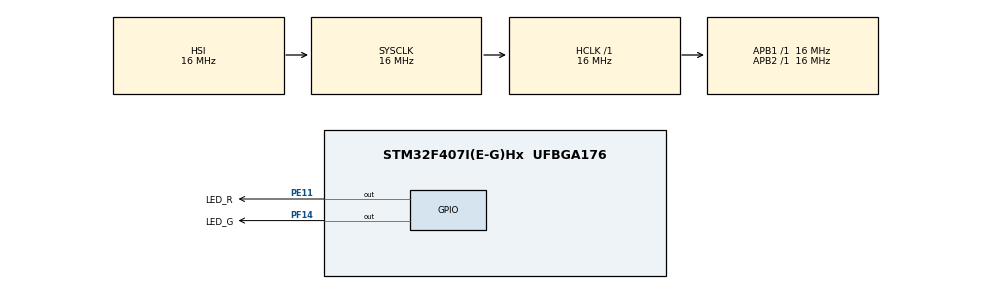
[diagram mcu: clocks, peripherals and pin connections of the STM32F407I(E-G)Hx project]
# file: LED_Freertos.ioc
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FREERTOS.Tasks01=LED_R,-1,128,StartDefaultTask,Default,NULL,Dynamic,NULL,NULL;LED_G,0,128,StartTask02,Default,NULL,Dynamic,NULL,NULL
Mcu.Family=STM32F4
Mcu.Name=STM32F407I(E-G)Hx
Mcu.Package=UFBGA176
NVIC.PriorityGroup=NVIC_PRIORITYGROUP_4
NVIC.TIM1_UP_TIM10_IRQn=true\:15\:0\:false\:false\:true\:false\:false\:true\:true
NVIC.TimeBase=TIM1_UP_TIM10_IRQn
NVIC.TimeBaseIP=TIM1
PA13.Mode=Serial_Wire
PA13.Signal=SYS_JTMS-SWDIO
PA14.Mode=Serial_Wire
PA14.Signal=SYS_JTCK-SWCLK
PC14-OSC32_IN.Mode=LSE-External-Oscillator
PC14-OSC32_IN.Signal=RCC_OSC32_IN
PC15-OSC32_OUT.Mode=LSE-External-Oscillator
PC15-OSC32_OUT.Signal=RCC_OSC32_OUT
PE11.GPIO_Label=LED_R
PE11.Signal=GPIO_Output
PF14.GPIO_Label=LED_G
PF14.Signal=GPIO_Output
PH0-OSC_IN.Mode=HSE-External-Oscillator
PH0-OSC_IN.Signal=RCC_OSC_IN
PH1-OSC_OUT.Mode=HSE-External-Oscillator
PH1-OSC_OUT.Signal=RCC_OSC_OUT
ProjectManager.HeapSize=0x200
ProjectManager.StackSize=0x400
ProjectManager.TargetToolchain=MDK-ARM V5.32
RCC.AHBFreq_Value=16000000
RCC.APB1Freq_Value=16000000
RCC.APB2Freq_Value=16000000
RCC.CortexFreq_Value=16000000
RCC.HSE_VALUE=25000000
RCC.HSI_VALUE=16000000
RCC.SYSCLKFreq_VALUE=16000000
RCC.VCOOutputFreq_Value=192000000
VP_FREERTOS_VS_CMSIS_V1.Mode=CMSIS_V1
VP_SYS_VS_tim1.Mode=TIM1
board=custom

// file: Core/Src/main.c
/* USER CODE BEGIN Header */
/**
  ******************************************************************************
  * @file           : main.c
  * @brief          : Main program body
  ******************************************************************************
  * @attention
  *
  * Copyright (c) 2023 STMicroelectronics.
  * All rights reserved.
  *
  * This software is licensed under terms that can be found in the LICENSE file
  * in the root directory of this software component.
  * If no LICENSE file comes with this software, it is provided AS-IS.
  *
  ******************************************************************************
  */
/* USER CODE END Header */
#include "main.h"
#include "cmsis_os.h"
#include "gpio.h"

void SystemClock_Config(void);
void MX_FREERTOS_Init(void);

int main(void)
{

  /* MCU Configuration--------------------------------------------------------*/

  /* Reset of all peripherals, Initializes the Flash interface and the Systick. */
  HAL_Init();

  /* Configure the system clock */
  SystemClock_Config();

  /* Initialize all configured peripherals */
  MX_GPIO_Init();

  /* Call init function for freertos objects (in freertos.c) */
  MX_FREERTOS_Init();

  /* Start scheduler */
  osKernelStart();
  /* We should never get here as control is now taken by the scheduler */
  /* Infinite loop */
  while (1)
  {

  }
}

void SystemClock_Config(void)
{
  RCC_OscInitTypeDef RCC_OscInitStruct = {0};
  RCC_ClkInitTypeDef RCC_ClkInitStruct = {0};

  /** Configure the main internal regulator output voltage
  */
  __HAL_RCC_PWR_CLK_ENABLE();
  __HAL_PWR_VOLTAGESCALING_CONFIG(PWR_REGULATOR_VOLTAGE_SCALE1);

  /** Initializes the RCC Oscillators according to the specified parameters
  * in the RCC_OscInitTypeDef structure.
  */
  RCC_OscInitStruct.OscillatorType = RCC_OSCILLATORTYPE_HSI;
  RCC_OscInitStruct.HSIState = RCC_HSI_ON;
  RCC_OscInitStruct.HSICalibrationValue = RCC_HSICALIBRATION_DEFAULT;
  RCC_OscInitStruct.PLL.PLLState = RCC_PLL_NONE;
  if (HAL_RCC_OscConfig(&RCC_OscInitStruct) != HAL_OK)
  {
    Error_Handler();
  }

  /** Initializes the CPU, AHB and APB buses clocks
  */
  RCC_ClkInitStruct.ClockType = RCC_CLOCKTYPE_HCLK|RCC_CLOCKTYPE_SYSCLK
                              |RCC_CLOCKTYPE_PCLK1|RCC_CLOCKTYPE_PCLK2;
  RCC_ClkInitStruct.SYSCLKSource = RCC_SYSCLKSOURCE_HSI;
  RCC_ClkInitStruct.AHBCLKDivider = RCC_SYSCLK_DIV1;
  RCC_ClkInitStruct.APB1CLKDivider = RCC_HCLK_DIV1;
  RCC_ClkInitStruct.APB2CLKDivider = RCC_HCLK_DIV1;

  if (HAL_RCC_ClockConfig(&RCC_ClkInitStruct, FLASH_LATENCY_0) != HAL_OK)
  {
    Error_Handler();
  }
}

void HAL_TIM_PeriodElapsedCallback(TIM_HandleTypeDef *htim)
{
  if (htim->Instance == TIM1) {
    HAL_IncTick();
  }
}

void Error_Handler(void)
{
  __disable_irq();
  while (1)
  {
  }
}

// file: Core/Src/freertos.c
/* USER CODE BEGIN Header */
/**
  ******************************************************************************
  * File Name          : freertos.c
  * Description        : Code for freertos applications
  ******************************************************************************
  * @attention
  *
  * Copyright (c) 2023 STMicroelectronics.
  * All rights reserved.
  *
  * This software is licensed under terms that can be found in the LICENSE file
  * in the root directory of this software component.
  * If no LICENSE file comes with this software, it is provided AS-IS.
  *
  ******************************************************************************
  */
/* USER CODE END Header */

#include "FreeRTOS.h"
#include "task.h"
#include "main.h"
#include "cmsis_os.h"

osThreadId LED_RHandle;
osThreadId LED_GHandle;

void StartDefaultTask(void const * argument);
void StartTask02(void const * argument);

void MX_FREERTOS_Init(void); /* (MISRA C 2004 rule 8.1) */

/* GetIdleTaskMemory prototype (linked to static allocation support) */
void vApplicationGetIdleTaskMemory( StaticTask_t **ppxIdleTaskTCBBuffer, StackType_t **ppxIdleTaskStackBuffer, uint32_t *pulIdleTaskStackSize );

/* USER CODE BEGIN GET_IDLE_TASK_MEMORY */
static StaticTask_t xIdleTaskTCBBuffer;
static StackType_t xIdleStack[configMINIMAL_STACK_SIZE];

void vApplicationGetIdleTaskMemory( StaticTask_t **ppxIdleTaskTCBBuffer, StackType_t **ppxIdleTaskStackBuffer, uint32_t *pulIdleTaskStackSize )
{
  *ppxIdleTaskTCBBuffer = &xIdleTaskTCBBuffer;
  *ppxIdleTaskStackBuffer = &xIdleStack[0];
  *pulIdleTaskStackSize = configMINIMAL_STACK_SIZE;
  /* place for user code */
}
/* USER CODE END GET_IDLE_TASK_MEMORY */

void MX_FREERTOS_Init(void) {

  /* Create the thread(s) */
  /* definition and creation of LED_R */
  osThreadDef(LED_R, StartDefaultTask, osPriorityBelowNormal, 0, 128);
  LED_RHandle = osThreadCreate(osThread(LED_R), NULL);

  /* definition and creation of LED_G */
  osThreadDef(LED_G, StartTask02, osPriorityNormal, 0, 128);
  LED_GHandle = osThreadCreate(osThread(LED_G), NULL);

}

void StartDefaultTask(void const * argument)
{
  /* USER CODE BEGIN StartDefaultTask */
  /* Infinite loop */
  for(;;)
  {
    HAL_GPIO_WritePin(LED_R_GPIO_Port,LED_R_Pin,GPIO_PIN_RESET);
    osDelay(1);
	HAL_GPIO_WritePin(LED_R_GPIO_Port,LED_R_Pin,GPIO_PIN_RESET);
    osDelay(1);
	HAL_GPIO_WritePin(LED_R_GPIO_Port,LED_R_Pin,GPIO_PIN_SET);
    osDelay(1);
  }
  /* USER CODE END StartDefaultTask */
}

void StartTask02(void const * argument)
{
  /* USER CODE BEGIN StartTask02 */
  /* Infinite loop */
  for(;;)
  {
	HAL_GPIO_WritePin(LED_G_GPIO_Port,LED_G_Pin,GPIO_PIN_RESET);
    osDelay(1);
	HAL_GPIO_WritePin(LED_G_GPIO_Port,LED_G_Pin,GPIO_PIN_RESET);
    osDelay(1);
	HAL_GPIO_WritePin(LED_G_GPIO_Port,LED_G_Pin,GPIO_PIN_SET);
    osDelay(1);
  }
  /* USER CODE END StartTask02 */
}
